# UPD70F3508 register map
Vendor: Renesas; Series: V850E2/Px4; File version: 1.0
CPU: other r0p0, little endian, no MPU, FPU, 4 interrupt priority bits
Registers are 8-bit, read-write, reset 0x0 unless marked. A register's access mark holds for its fields unless they carry their own. Offsets are from the block's base; [hi:lo] are bit positions; {n}, {i} and the like mark numbered series.

## ADCA0_DATA — A/D Converter A0 - Data/Status/Trigger register block (ADCAn_base1=0xFFFFDC00, offsets 0x00-0xDD)
Base 0xFFFFDC00
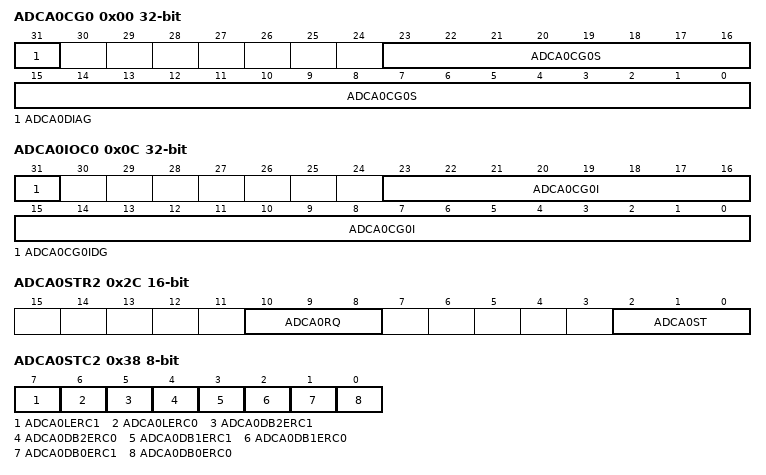
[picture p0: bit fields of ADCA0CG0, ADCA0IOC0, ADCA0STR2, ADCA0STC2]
0x00 ADCA0CG0 32-bit — A/D Converter Channel Group Register 0 (scan list)
  [31] ADCA0DIAG — Enable diagnostic ADDIAGOUT conversion after CG0 scan (CG0 only)
  [23:0] ADCA0CG0S — Channel scan list bitmask for CG0 (bit n-1=CHn, bits 23:0)
0x04 ADCA0CG1 32-bit — A/D Converter Channel Group Register 1 (scan list)
  [23:0] ADCA0CG1S — Channel scan list bitmask for CG1 (bit n-1=CHn, bits 23:0)
0x08 ADCA0CG2 32-bit — A/D Converter Channel Group Register 2 (scan list)
  [23:0] ADCA0CG2S — Channel scan list bitmask for CG2 (bit n-1=CHn, bits 23:0)
0x0C ADCA0IOC0 32-bit — A/D Converter Interrupt Control Register 0
  [31] ADCA0CG0IDG — Generate INTADCAnT0 on diagnostic conversion completion (CG0 only)
  [23:0] ADCA0CG0I — Interrupt enable per channel for CG0 (bit n-1=CHn, 0=no INT, 1=INT)
0x10 ADCA0IOC1 32-bit — A/D Converter Interrupt Control Register 1
  [23:0] ADCA0CG1I — Interrupt enable per channel for CG1 (bit n-1=CHn, 0=no INT, 1=INT)
0x14 ADCA0IOC2 32-bit — A/D Converter Interrupt Control Register 2
  [23:0] ADCA0CG2I — Interrupt enable per channel for CG2 (bit n-1=CHn, 0=no INT, 1=INT)
0x18 ADCA0CTL2 32-bit — A/D Conversion Result Check Register (upper/lower limit enable per channel)
  [23:0] ADCA0RCK — Upper/lower limit comparison enable per channel (bit n-1=CHn)
0x1C ADCA0UL 16-bit — A/D Conversion Result Upper Limit
  [11:0] ADCA0ULV — Upper limit value for result range check (bits 11:0)
0x20 ADCA0LL 16-bit — A/D Conversion Result Lower Limit
  [11:0] ADCA0LLV — Lower limit value for result range check (bits 11:0)
0x24 ADCA0STR0 32-bit ro — A/D Converter Result Upper/Lower Limit Comparison Error Flag
  [23:0] ADCA0RCE — Result out-of-range error per channel (bit n-1=CHn)
0x28 ADCA0STR1 32-bit ro — A/D Converter Overwrite Error Flag Register
  [23:0] ADCA0OWE — Overwrite error per channel (bit n-1=CHn)
0x2C ADCA0STR2 16-bit ro — A/D Converter Status Flag Register 2
  [10:8] ADCA0RQ — Conversion request pending per CG (bits 10:8, bit i=CGi)
  [2:0] ADCA0ST — Conversion currently active per CG (bits 2:0, bit i=CGi)
0x30 ADCA0STC0 32-bit wo — ADCAnSTR0 Flag Clear Register
  [23:0] ADCA0RCEC — Clear result range error flags (write 1 to clear; bit n-1=CHn)
0x34 ADCA0STC1 32-bit wo — ADCAnSTR1 Flag Clear Register
  [23:0] ADCA0OWEC — Clear overwrite error flags (write 1 to clear; bit n-1=CHn)
0x38 ADCA0STC2 wo — ADCAnSTR2 Flag Clear Register
  [7] ADCA0LERC1 — Clear LCR overwrite flag (write 1 to clear)
  [6] ADCA0LERC0 — Clear LCR result-check error flag
  [5] ADCA0DB2ERC1 — Clear DB2CR overwrite flag
  [4] ADCA0DB2ERC0 — Clear DB2CR result-check error flag
  [3] ADCA0DB1ERC1 — Clear DB1CR overwrite flag
  [2] ADCA0DB1ERC0 — Clear DB1CR result-check error flag
  [1] ADCA0DB0ERC1 — Clear DB0CR overwrite flag
  [0] ADCA0DB0ERC0 — Clear DB0CR result-check error flag
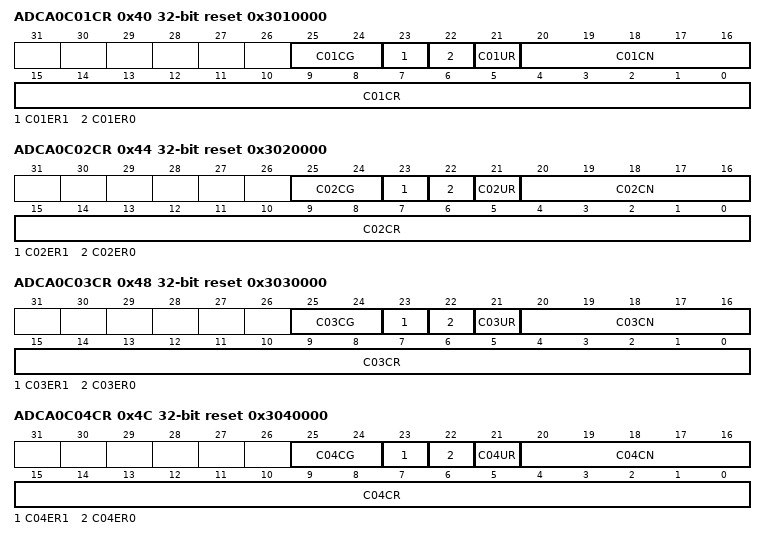
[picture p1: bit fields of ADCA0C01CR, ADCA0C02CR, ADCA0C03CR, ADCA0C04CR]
0x40 ADCA0C01CR 32-bit ro reset 0x3010000 — A/D Converter Conversion Result Register Channel 1
  [25:24] C01CG — CG that produced CH1 result (00=CG0,01=CG1,10=CG2,11=none)
  [23] C01ER1 — Overwrite error for CH1 (mirrors STR1.OWEm)
  [22] C01ER0 — Result range error for CH1 (mirrors STR0.RCEm)
  [21] C01UR — Unread flag for CH1 (1=not yet read)
  [20:16] C01CN — Channel number of stored result (bits 20:16; fixed = 0x01)
  [15:0] C01CR — A/D conversion result value for CH1 (bits 15:0)
0x44 ADCA0C02CR 32-bit ro reset 0x3020000 — A/D Converter Conversion Result Register Channel 2
  [25:24] C02CG — CG that produced CH2 result (00=CG0,01=CG1,10=CG2,11=none)
  [23] C02ER1 — Overwrite error for CH2 (mirrors STR1.OWEm)
  [22] C02ER0 — Result range error for CH2 (mirrors STR0.RCEm)
  [21] C02UR — Unread flag for CH2 (1=not yet read)
  [20:16] C02CN — Channel number of stored result (bits 20:16; fixed = 0x02)
  [15:0] C02CR — A/D conversion result value for CH2 (bits 15:0)
0x48 ADCA0C03CR 32-bit ro reset 0x3030000 — A/D Converter Conversion Result Register Channel 3
  [25:24] C03CG — CG that produced CH3 result (00=CG0,01=CG1,10=CG2,11=none)
  [23] C03ER1 — Overwrite error for CH3 (mirrors STR1.OWEm)
  [22] C03ER0 — Result range error for CH3 (mirrors STR0.RCEm)
  [21] C03UR — Unread flag for CH3 (1=not yet read)
  [20:16] C03CN — Channel number of stored result (bits 20:16; fixed = 0x03)
  [15:0] C03CR — A/D conversion result value for CH3 (bits 15:0)
0x4C ADCA0C04CR 32-bit ro reset 0x3040000 — A/D Converter Conversion Result Register Channel 4
  [25:24] C04CG — CG that produced CH4 result (00=CG0,01=CG1,10=CG2,11=none)
  [23] C04ER1 — Overwrite error for CH4 (mirrors STR1.OWEm)
  [22] C04ER0 — Result range error for CH4 (mirrors STR0.RCEm)
  [21] C04UR — Unread flag for CH4 (1=not yet read)
  [20:16] C04CN — Channel number of stored result (bits 20:16; fixed = 0x04)
  [15:0] C04CR — A/D conversion result value for CH4 (bits 15:0)
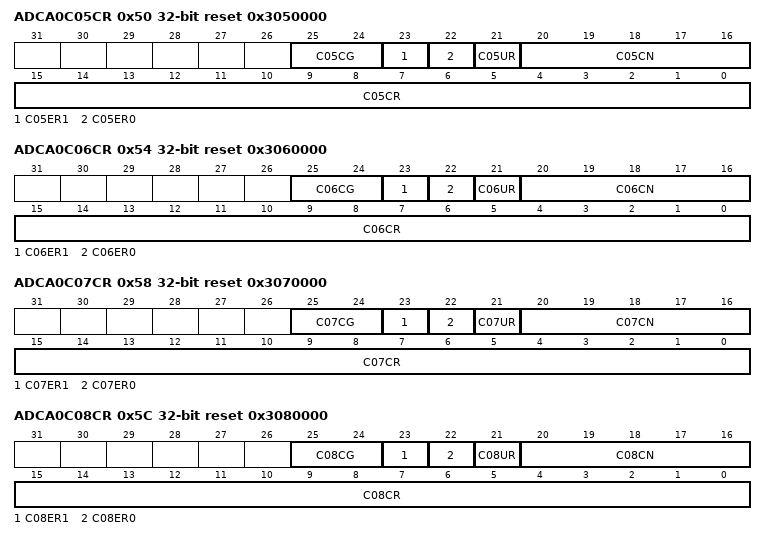
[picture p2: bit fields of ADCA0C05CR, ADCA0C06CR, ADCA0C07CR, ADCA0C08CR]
0x50 ADCA0C05CR 32-bit ro reset 0x3050000 — A/D Converter Conversion Result Register Channel 5
  [25:24] C05CG — CG that produced CH5 result (00=CG0,01=CG1,10=CG2,11=none)
  [23] C05ER1 — Overwrite error for CH5 (mirrors STR1.OWEm)
  [22] C05ER0 — Result range error for CH5 (mirrors STR0.RCEm)
  [21] C05UR — Unread flag for CH5 (1=not yet read)
  [20:16] C05CN — Channel number of stored result (bits 20:16; fixed = 0x05)
  [15:0] C05CR — A/D conversion result value for CH5 (bits 15:0)
0x54 ADCA0C06CR 32-bit ro reset 0x3060000 — A/D Converter Conversion Result Register Channel 6
  [25:24] C06CG — CG that produced CH6 result (00=CG0,01=CG1,10=CG2,11=none)
  [23] C06ER1 — Overwrite error for CH6 (mirrors STR1.OWEm)
  [22] C06ER0 — Result range error for CH6 (mirrors STR0.RCEm)
  [21] C06UR — Unread flag for CH6 (1=not yet read)
  [20:16] C06CN — Channel number of stored result (bits 20:16; fixed = 0x06)
  [15:0] C06CR — A/D conversion result value for CH6 (bits 15:0)
0x58 ADCA0C07CR 32-bit ro reset 0x3070000 — A/D Converter Conversion Result Register Channel 7
  [25:24] C07CG — CG that produced CH7 result (00=CG0,01=CG1,10=CG2,11=none)
  [23] C07ER1 — Overwrite error for CH7 (mirrors STR1.OWEm)
  [22] C07ER0 — Result range error for CH7 (mirrors STR0.RCEm)
  [21] C07UR — Unread flag for CH7 (1=not yet read)
  [20:16] C07CN — Channel number of stored result (bits 20:16; fixed = 0x07)
  [15:0] C07CR — A/D conversion result value for CH7 (bits 15:0)
0x5C ADCA0C08CR 32-bit ro reset 0x3080000 — A/D Converter Conversion Result Register Channel 8
  [25:24] C08CG — CG that produced CH8 result (00=CG0,01=CG1,10=CG2,11=none)
  [23] C08ER1 — Overwrite error for CH8 (mirrors STR1.OWEm)
  [22] C08ER0 — Result range error for CH8 (mirrors STR0.RCEm)
  [21] C08UR — Unread flag for CH8 (1=not yet read)
  [20:16] C08CN — Channel number of stored result (bits 20:16; fixed = 0x08)
  [15:0] C08CR — A/D conversion result value for CH8 (bits 15:0)
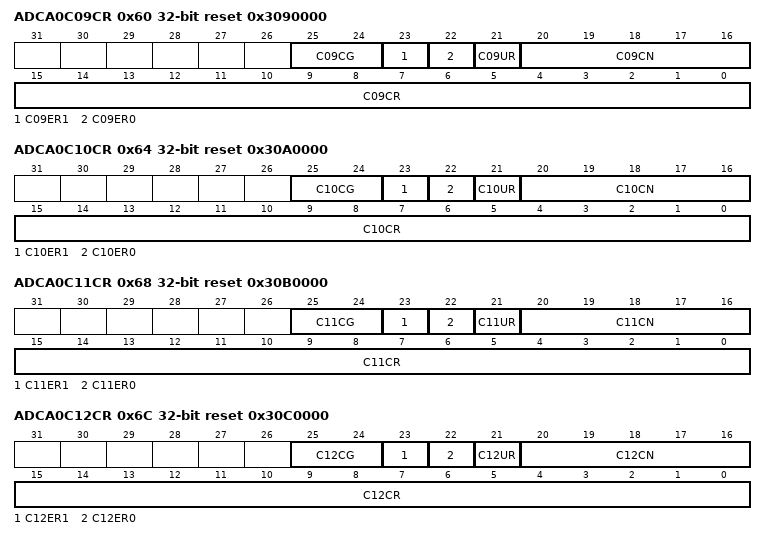
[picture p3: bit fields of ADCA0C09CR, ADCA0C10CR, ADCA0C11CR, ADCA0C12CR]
0x60 ADCA0C09CR 32-bit ro reset 0x3090000 — A/D Converter Conversion Result Register Channel 9
  [25:24] C09CG — CG that produced CH9 result (00=CG0,01=CG1,10=CG2,11=none)
  [23] C09ER1 — Overwrite error for CH9 (mirrors STR1.OWEm)
  [22] C09ER0 — Result range error for CH9 (mirrors STR0.RCEm)
  [21] C09UR — Unread flag for CH9 (1=not yet read)
  [20:16] C09CN — Channel number of stored result (bits 20:16; fixed = 0x09)
  [15:0] C09CR — A/D conversion result value for CH9 (bits 15:0)
0x64 ADCA0C10CR 32-bit ro reset 0x30A0000 — A/D Converter Conversion Result Register Channel 10
  [25:24] C10CG — CG that produced CH10 result (00=CG0,01=CG1,10=CG2,11=none)
  [23] C10ER1 — Overwrite error for CH10 (mirrors STR1.OWEm)
  [22] C10ER0 — Result range error for CH10 (mirrors STR0.RCEm)
  [21] C10UR — Unread flag for CH10 (1=not yet read)
  [20:16] C10CN — Channel number of stored result (bits 20:16; fixed = 0x0A)
  [15:0] C10CR — A/D conversion result value for CH10 (bits 15:0)
0x68 ADCA0C11CR 32-bit ro reset 0x30B0000 — A/D Converter Conversion Result Register Channel 11
  [25:24] C11CG — CG that produced CH11 result (00=CG0,01=CG1,10=CG2,11=none)
  [23] C11ER1 — Overwrite error for CH11 (mirrors STR1.OWEm)
  [22] C11ER0 — Result range error for CH11 (mirrors STR0.RCEm)
  [21] C11UR — Unread flag for CH11 (1=not yet read)
  [20:16] C11CN — Channel number of stored result (bits 20:16; fixed = 0x0B)
  [15:0] C11CR — A/D conversion result value for CH11 (bits 15:0)
0x6C ADCA0C12CR 32-bit ro reset 0x30C0000 — A/D Converter Conversion Result Register Channel 12
  [25:24] C12CG — CG that produced CH12 result (00=CG0,01=CG1,10=CG2,11=none)
  [23] C12ER1 — Overwrite error for CH12 (mirrors STR1.OWEm)
  [22] C12ER0 — Result range error for CH12 (mirrors STR0.RCEm)
  [21] C12UR — Unread flag for CH12 (1=not yet read)
  [20:16] C12CN — Channel number of stored result (bits 20:16; fixed = 0x0C)
  [15:0] C12CR — A/D conversion result value for CH12 (bits 15:0)
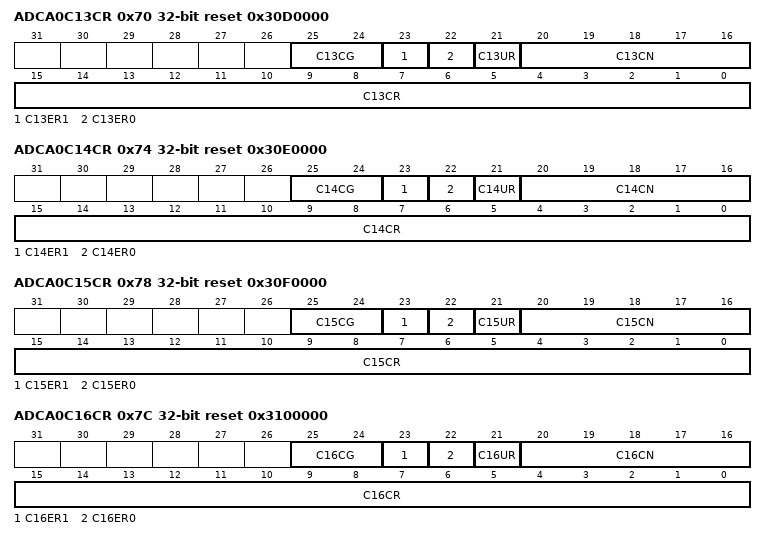
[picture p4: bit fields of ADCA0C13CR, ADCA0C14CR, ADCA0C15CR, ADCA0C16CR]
0x70 ADCA0C13CR 32-bit ro reset 0x30D0000 — A/D Converter Conversion Result Register Channel 13
  [25:24] C13CG — CG that produced CH13 result (00=CG0,01=CG1,10=CG2,11=none)
  [23] C13ER1 — Overwrite error for CH13 (mirrors STR1.OWEm)
  [22] C13ER0 — Result range error for CH13 (mirrors STR0.RCEm)
  [21] C13UR — Unread flag for CH13 (1=not yet read)
  [20:16] C13CN — Channel number of stored result (bits 20:16; fixed = 0x0D)
  [15:0] C13CR — A/D conversion result value for CH13 (bits 15:0)
0x74 ADCA0C14CR 32-bit ro reset 0x30E0000 — A/D Converter Conversion Result Register Channel 14
  [25:24] C14CG — CG that produced CH14 result (00=CG0,01=CG1,10=CG2,11=none)
  [23] C14ER1 — Overwrite error for CH14 (mirrors STR1.OWEm)
  [22] C14ER0 — Result range error for CH14 (mirrors STR0.RCEm)
  [21] C14UR — Unread flag for CH14 (1=not yet read)
  [20:16] C14CN — Channel number of stored result (bits 20:16; fixed = 0x0E)
  [15:0] C14CR — A/D conversion result value for CH14 (bits 15:0)
0x78 ADCA0C15CR 32-bit ro reset 0x30F0000 — A/D Converter Conversion Result Register Channel 15
  [25:24] C15CG — CG that produced CH15 result (00=CG0,01=CG1,10=CG2,11=none)
  [23] C15ER1 — Overwrite error for CH15 (mirrors STR1.OWEm)
  [22] C15ER0 — Result range error for CH15 (mirrors STR0.RCEm)
  [21] C15UR — Unread flag for CH15 (1=not yet read)
  [20:16] C15CN — Channel number of stored result (bits 20:16; fixed = 0x0F)
  [15:0] C15CR — A/D conversion result value for CH15 (bits 15:0)
0x7C ADCA0C16CR 32-bit ro reset 0x3100000 — A/D Converter Conversion Result Register Channel 16
  [25:24] C16CG — CG that produced CH16 result (00=CG0,01=CG1,10=CG2,11=none)
  [23] C16ER1 — Overwrite error for CH16 (mirrors STR1.OWEm)
  [22] C16ER0 — Result range error for CH16 (mirrors STR0.RCEm)
  [21] C16UR — Unread flag for CH16 (1=not yet read)
  [20:16] C16CN — Channel number of stored result (bits 20:16; fixed = 0x10)
  [15:0] C16CR — A/D conversion result value for CH16 (bits 15:0)
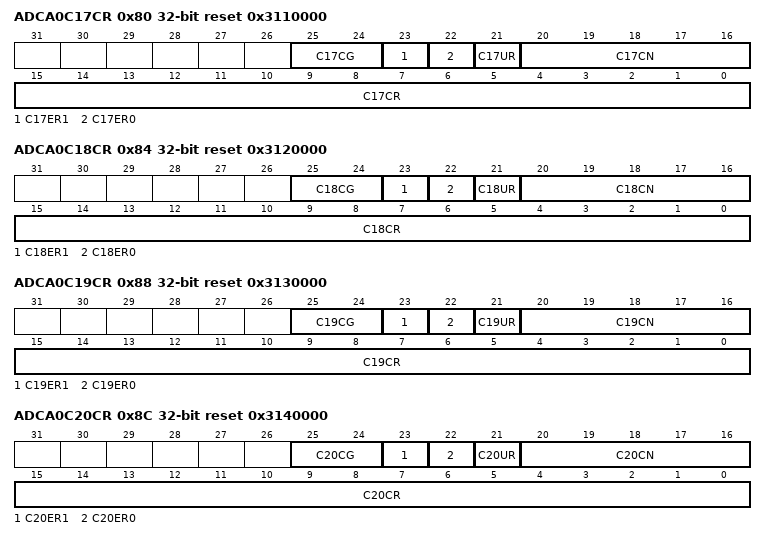
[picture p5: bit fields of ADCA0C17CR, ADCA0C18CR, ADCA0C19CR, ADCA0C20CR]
0x80 ADCA0C17CR 32-bit ro reset 0x3110000 — A/D Converter Conversion Result Register Channel 17
  [25:24] C17CG — CG that produced CH17 result (00=CG0,01=CG1,10=CG2,11=none)
  [23] C17ER1 — Overwrite error for CH17 (mirrors STR1.OWEm)
  [22] C17ER0 — Result range error for CH17 (mirrors STR0.RCEm)
  [21] C17UR — Unread flag for CH17 (1=not yet read)
  [20:16] C17CN — Channel number of stored result (bits 20:16; fixed = 0x11)
  [15:0] C17CR — A/D conversion result value for CH17 (bits 15:0)
0x84 ADCA0C18CR 32-bit ro reset 0x3120000 — A/D Converter Conversion Result Register Channel 18
  [25:24] C18CG — CG that produced CH18 result (00=CG0,01=CG1,10=CG2,11=none)
  [23] C18ER1 — Overwrite error for CH18 (mirrors STR1.OWEm)
  [22] C18ER0 — Result range error for CH18 (mirrors STR0.RCEm)
  [21] C18UR — Unread flag for CH18 (1=not yet read)
  [20:16] C18CN — Channel number of stored result (bits 20:16; fixed = 0x12)
  [15:0] C18CR — A/D conversion result value for CH18 (bits 15:0)
0x88 ADCA0C19CR 32-bit ro reset 0x3130000 — A/D Converter Conversion Result Register Channel 19
  [25:24] C19CG — CG that produced CH19 result (00=CG0,01=CG1,10=CG2,11=none)
  [23] C19ER1 — Overwrite error for CH19 (mirrors STR1.OWEm)
  [22] C19ER0 — Result range error for CH19 (mirrors STR0.RCEm)
  [21] C19UR — Unread flag for CH19 (1=not yet read)
  [20:16] C19CN — Channel number of stored result (bits 20:16; fixed = 0x13)
  [15:0] C19CR — A/D conversion result value for CH19 (bits 15:0)
0x8C ADCA0C20CR 32-bit ro reset 0x3140000 — A/D Converter Conversion Result Register Channel 20
  [25:24] C20CG — CG that produced CH20 result (00=CG0,01=CG1,10=CG2,11=none)
  [23] C20ER1 — Overwrite error for CH20 (mirrors STR1.OWEm)
  [22] C20ER0 — Result range error for CH20 (mirrors STR0.RCEm)
  [21] C20UR — Unread flag for CH20 (1=not yet read)
  [20:16] C20CN — Channel number of stored result (bits 20:16; fixed = 0x14)
  [15:0] C20CR — A/D conversion result value for CH20 (bits 15:0)
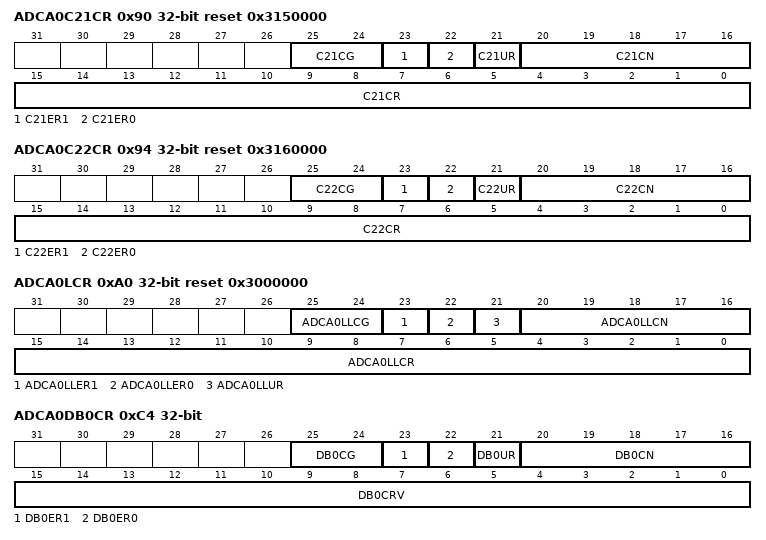
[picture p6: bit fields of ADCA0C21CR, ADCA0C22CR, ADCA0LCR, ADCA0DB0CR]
0x90 ADCA0C21CR 32-bit ro reset 0x3150000 — A/D Converter Conversion Result Register Channel 21
  [25:24] C21CG — CG that produced CH21 result (00=CG0,01=CG1,10=CG2,11=none)
  [23] C21ER1 — Overwrite error for CH21 (mirrors STR1.OWEm)
  [22] C21ER0 — Result range error for CH21 (mirrors STR0.RCEm)
  [21] C21UR — Unread flag for CH21 (1=not yet read)
  [20:16] C21CN — Channel number of stored result (bits 20:16; fixed = 0x15)
  [15:0] C21CR — A/D conversion result value for CH21 (bits 15:0)
0x94 ADCA0C22CR 32-bit ro reset 0x3160000 — A/D Converter Conversion Result Register Channel 22
  [25:24] C22CG — CG that produced CH22 result (00=CG0,01=CG1,10=CG2,11=none)
  [23] C22ER1 — Overwrite error for CH22 (mirrors STR1.OWEm)
  [22] C22ER0 — Result range error for CH22 (mirrors STR0.RCEm)
  [21] C22UR — Unread flag for CH22 (1=not yet read)
  [20:16] C22CN — Channel number of stored result (bits 20:16; fixed = 0x16)
  [15:0] C22CR — A/D conversion result value for CH22 (bits 15:0)
0x9C ADCA0DGCR 16-bit ro — A/D Converter Diagnosis Conversion Result Register
  [15:0] ADCA0DGCRV — Diagnostic A/D conversion result (resolution/alignment per CTL1)
0xA0 ADCA0LCR 32-bit ro reset 0x3000000 — A/D Converter Latest Conversion Result Register
  [25:24] ADCA0LLCG — CG of latest result (bits 25:24; 00=CG0,01=CG1,10=CG2,11=none)
  [23] ADCA0LLER1 — Overwrite error for latest result
  [22] ADCA0LLER0 — Result range error for latest result
  [21] ADCA0LLUR — Latest result unread flag
  [20:16] ADCA0LLCN — Channel number of latest result (bits 20:16)
  [15:0] ADCA0LLCR — Latest A/D conversion result value (bits 15:0)
{0xA4+4i} ADCA0TRG{i} wo (i=0..2) — A/D Converter Software Start Trigger Register {i} (CG{i})
  [0] ADCA0STT{i} — Write 1 to start A/D conversion of CG{i} (auto-clears)
{0xA4+4i} ADCA0TRG{i} wo (i=4..6) — A/D Converter Software Stop Trigger Register {i-4} (CG{i-4})
  [0] ADCA0SP{i-4} — Write 1 to stop A/D conversion of CG{i-4}
0xC4 ADCA0DB0CR 32-bit ro — A/D Converter CG0 DMA Buffer Register
  [25:24] DB0CG — CG identifier in buffer (bits 25:24; fixed to CG0)
  [23] DB0ER1 — Overwrite error for CG0 buffer result
  [22] DB0ER0 — Result range error for CG0 buffer result
  [21] DB0UR — Unread flag for CG0 buffer result
  [20:16] DB0CN — Channel number in CG0 buffer (bits 20:16)
  [15:0] DB0CRV — A/D conversion result value in CG0 buffer (bits 15:0)
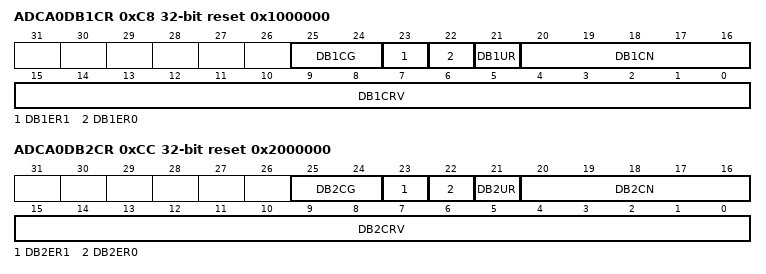
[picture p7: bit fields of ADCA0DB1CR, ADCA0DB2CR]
0xC8 ADCA0DB1CR 32-bit ro reset 0x1000000 — A/D Converter CG1 DMA Buffer Register
  [25:24] DB1CG — CG identifier in buffer (bits 25:24; fixed to CG1)
  [23] DB1ER1 — Overwrite error for CG1 buffer result
  [22] DB1ER0 — Result range error for CG1 buffer result
  [21] DB1UR — Unread flag for CG1 buffer result
  [20:16] DB1CN — Channel number in CG1 buffer (bits 20:16)
  [15:0] DB1CRV — A/D conversion result value in CG1 buffer (bits 15:0)
0xCC ADCA0DB2CR 32-bit ro reset 0x2000000 — A/D Converter CG2 DMA Buffer Register
  [25:24] DB2CG — CG identifier in buffer (bits 25:24; fixed to CG2)
  [23] DB2ER1 — Overwrite error for CG2 buffer result
  [22] DB2ER0 — Result range error for CG2 buffer result
  [21] DB2UR — Unread flag for CG2 buffer result
  [20:16] DB2CN — Channel number in CG2 buffer (bits 20:16)
  [15:0] DB2CRV — A/D conversion result value in CG2 buffer (bits 15:0)
{0xD0+4i} ADCA0DB{i}CRL 16-bit ro (i=0..2) — A/D Converter CG{i} DMA Buffer Register (Result Only, 16-bit)
  [15:0] DB{i}CRL — A/D conversion result for CG{i} (mirrors DB{i}CR bits 15:0)
0xDC ADCA0DGCTL0 16-bit — A/D Converter Self-Diagnosis Function Control Register 0
  [2:0] ADCA0PSEL — Reference voltage select for diagnostic conversion ADDIAGOUT (bits 2:0)
